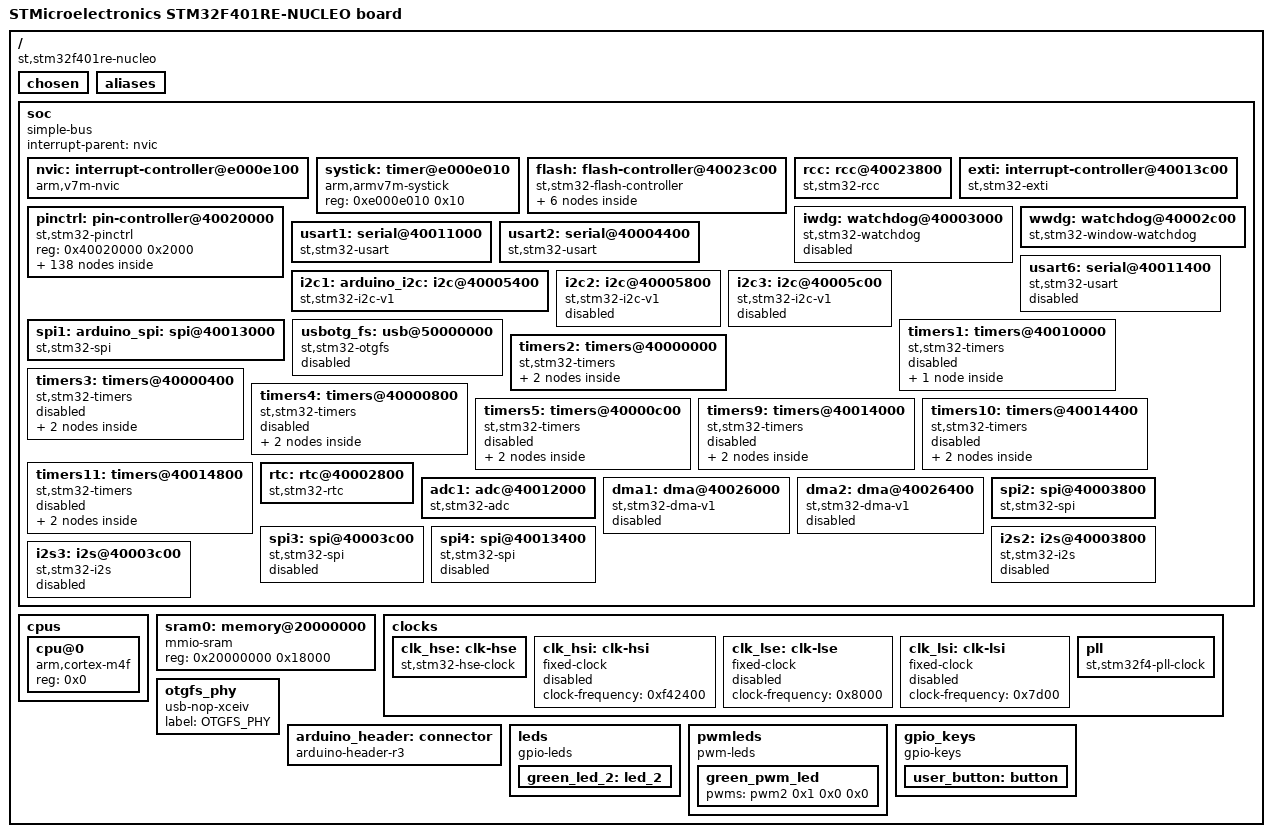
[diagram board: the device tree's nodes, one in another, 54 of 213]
/dts-v1/;

/ {
	#address-cells = < 0x1 >;
	#size-cells = < 0x1 >;
	model = "STMicroelectronics STM32F401RE-NUCLEO board";
	compatible = "st,stm32f401re-nucleo";
	chosen {
		zephyr,flash-controller = &flash;
		zephyr,console = &usart2;
		zephyr,shell-uart = &usart2;
		zephyr,sram = &sram0;
		zephyr,flash = &flash0;
		zephyr,code-partition = &slot0_partition;
	};
	aliases {
		led0 = &green_led_2;
		sw0 = &user_button;
		pwm-led0 = &green_pwm_led;
	};
	soc {
		#address-cells = < 0x1 >;
		#size-cells = < 0x1 >;
		compatible = "simple-bus";
		interrupt-parent = < &nvic >;
		ranges;
		nvic: interrupt-controller@e000e100 {
			#address-cells = < 0x1 >;
			compatible = "arm,v7m-nvic";
			reg = < 0xe000e100 0xc00 >;
			interrupt-controller;
			#interrupt-cells = < 0x2 >;
			arm,num-irq-priority-bits = < 0x4 >;
			phandle = < 0x1 >;
		};
		systick: timer@e000e010 {
			compatible = "arm,armv7m-systick";
			reg = < 0xe000e010 0x10 >;
		};
		flash: flash-controller@40023c00 {
			compatible = "st,stm32-flash-controller", "st,stm32f4-flash-controller";
			label = "FLASH_CTRL";
			reg = < 0x40023c00 0x400 >;
			interrupts = < 0x4 0x0 >;
			#address-cells = < 0x1 >;
			#size-cells = < 0x1 >;
			flash0: flash@8000000 {
				compatible = "st,stm32-nv-flash", "soc-nv-flash";
				label = "FLASH_STM32";
				write-block-size = < 0x1 >;
				max-erase-time = < 0xfa0 >;
				reg = < 0x8000000 0x80000 >;
				partitions {
					compatible = "fixed-partitions";
					#address-cells = < 0x1 >;
					#size-cells = < 0x1 >;
					boot_partition: partition@0 {
						label = "mcuboot";
						reg = < 0x0 0x10000 >;
						read-only;
					};
					slot0_partition: partition@20000 {
						label = "image-0";
						reg = < 0x20000 0x20000 >;
					};
					slot1_partition: partition@40000 {
						label = "image-1";
						reg = < 0x40000 0x20000 >;
					};
					scratch_partition: partition@60000 {
						label = "image-scratch";
						reg = < 0x60000 0x20000 >;
					};
				};
			};
		};
		rcc: rcc@40023800 {
			compatible = "st,stm32-rcc";
			#clock-cells = < 0x2 >;
			reg = < 0x40023800 0x400 >;
			clocks = < &pll >;
			clock-frequency = < 0x501bd00 >;
			ahb-prescaler = < 0x1 >;
			apb1-prescaler = < 0x2 >;
			apb2-prescaler = < 0x1 >;
			phandle = < 0x3 >;
		};
		exti: interrupt-controller@40013c00 {
			compatible = "st,stm32-exti";
			interrupt-controller;
			#interrupt-cells = < 0x1 >;
			reg = < 0x40013c00 0x400 >;
		};
		pinctrl: pin-controller@40020000 {
			compatible = "st,stm32-pinctrl";
			#address-cells = < 0x1 >;
			#size-cells = < 0x1 >;
			reg = < 0x40020000 0x2000 >;
			gpioa: gpio@40020000 {
				compatible = "st,stm32-gpio";
				gpio-controller;
				#gpio-cells = < 0x2 >;
				reg = < 0x40020000 0x400 >;
				clocks = < &rcc 0x0 0x1 >;
				label = "GPIOA";
				phandle = < 0x17 >;
			};
			gpiob: gpio@40020400 {
				compatible = "st,stm32-gpio";
				gpio-controller;
				#gpio-cells = < 0x2 >;
				reg = < 0x40020400 0x400 >;
				clocks = < &rcc 0x0 0x2 >;
				label = "GPIOB";
				phandle = < 0xd >;
			};
			gpioc: gpio@40020800 {
				compatible = "st,stm32-gpio";
				gpio-controller;
				#gpio-cells = < 0x2 >;
				reg = < 0x40020800 0x400 >;
				clocks = < &rcc 0x0 0x4 >;
				label = "GPIOC";
				phandle = < 0x18 >;
			};
			gpiod: gpio@40020c00 {
				compatible = "st,stm32-gpio";
				gpio-controller;
				#gpio-cells = < 0x2 >;
				reg = < 0x40020c00 0x400 >;
				clocks = < &rcc 0x0 0x8 >;
				label = "GPIOD";
			};
			gpioe: gpio@40021000 {
				compatible = "st,stm32-gpio";
				gpio-controller;
				#gpio-cells = < 0x2 >;
				reg = < 0x40021000 0x400 >;
				clocks = < &rcc 0x0 0x10 >;
				label = "GPIOE";
			};
			gpiof: gpio@40021400 {
				compatible = "st,stm32-gpio";
				gpio-controller;
				#gpio-cells = < 0x2 >;
				reg = < 0x40021400 0x400 >;
				clocks = < &rcc 0x0 0x20 >;
				label = "GPIOF";
			};
			gpiog: gpio@40021800 {
				compatible = "st,stm32-gpio";
				gpio-controller;
				#gpio-cells = < 0x2 >;
				reg = < 0x40021800 0x400 >;
				clocks = < &rcc 0x0 0x40 >;
				label = "GPIOG";
			};
			gpioh: gpio@40021c00 {
				compatible = "st,stm32-gpio";
				gpio-controller;
				#gpio-cells = < 0x2 >;
				reg = < 0x40021c00 0x400 >;
				clocks = < &rcc 0x0 0x80 >;
				label = "GPIOH";
			};
			adc1_in0_pa0: adc1_in0_pa0 {
				pinmux = < 0x10 >;
				phandle = < 0x10 >;
			};
			adc1_in1_pa1: adc1_in1_pa1 {
				pinmux = < 0x30 >;
			};
			adc1_in2_pa2: adc1_in2_pa2 {
				pinmux = < 0x50 >;
			};
			adc1_in3_pa3: adc1_in3_pa3 {
				pinmux = < 0x70 >;
			};
			adc1_in4_pa4: adc1_in4_pa4 {
				pinmux = < 0x90 >;
			};
			adc1_in5_pa5: adc1_in5_pa5 {
				pinmux = < 0xb0 >;
			};
			adc1_in6_pa6: adc1_in6_pa6 {
				pinmux = < 0xd0 >;
			};
			adc1_in7_pa7: adc1_in7_pa7 {
				pinmux = < 0xf0 >;
			};
			adc1_in8_pb0: adc1_in8_pb0 {
				pinmux = < 0x210 >;
			};
			adc1_in9_pb1: adc1_in9_pb1 {
				pinmux = < 0x230 >;
			};
			adc1_in10_pc0: adc1_in10_pc0 {
				pinmux = < 0x410 >;
			};
			adc1_in11_pc1: adc1_in11_pc1 {
				pinmux = < 0x430 >;
			};
			adc1_in12_pc2: adc1_in12_pc2 {
				pinmux = < 0x450 >;
			};
			adc1_in13_pc3: adc1_in13_pc3 {
				pinmux = < 0x470 >;
			};
			adc1_in14_pc4: adc1_in14_pc4 {
				pinmux = < 0x490 >;
			};
			adc1_in15_pc5: adc1_in15_pc5 {
				pinmux = < 0x4b0 >;
			};
			i2c1_scl_pb6: i2c1_scl_pb6 {
				pinmux = < 0x2c4 >;
				bias-pull-up;
				drive-open-drain;
			};
			i2c1_scl_pb8: i2c1_scl_pb8 {
				pinmux = < 0x304 >;
				bias-pull-up;
				drive-open-drain;
				phandle = < 0x8 >;
			};
			i2c2_scl_pb10: i2c2_scl_pb10 {
				pinmux = < 0x344 >;
				bias-pull-up;
				drive-open-drain;
			};
			i2c3_scl_pa8: i2c3_scl_pa8 {
				pinmux = < 0x104 >;
				bias-pull-up;
				drive-open-drain;
			};
			i2c1_sda_pb7: i2c1_sda_pb7 {
				pinmux = < 0x2e4 >;
				bias-pull-up;
				drive-open-drain;
			};
			i2c1_sda_pb9: i2c1_sda_pb9 {
				pinmux = < 0x324 >;
				bias-pull-up;
				drive-open-drain;
				phandle = < 0x9 >;
			};
			i2c2_sda_pb3: i2c2_sda_pb3 {
				pinmux = < 0x269 >;
				bias-pull-up;
				drive-open-drain;
			};
			i2c3_sda_pb4: i2c3_sda_pb4 {
				pinmux = < 0x289 >;
				bias-pull-up;
				drive-open-drain;
			};
			i2c3_sda_pc9: i2c3_sda_pc9 {
				pinmux = < 0x524 >;
				bias-pull-up;
				drive-open-drain;
			};
			i2s2_ck_pb10: i2s2_ck_pb10 {
				pinmux = < 0x345 >;
				slew-rate = "very-high-speed";
			};
			i2s2_ck_pb13: i2s2_ck_pb13 {
				pinmux = < 0x3a5 >;
				slew-rate = "very-high-speed";
			};
			i2s3_ck_pb3: i2s3_ck_pb3 {
				pinmux = < 0x266 >;
				slew-rate = "very-high-speed";
			};
			i2s3_ck_pc10: i2s3_ck_pc10 {
				pinmux = < 0x546 >;
				slew-rate = "very-high-speed";
			};
			i2s2_sd_pb15: i2s2_sd_pb15 {
				pinmux = < 0x3e5 >;
			};
			i2s2_sd_pc3: i2s2_sd_pc3 {
				pinmux = < 0x465 >;
			};
			i2s3_sd_pb5: i2s3_sd_pb5 {
				pinmux = < 0x2a6 >;
			};
			i2s3_sd_pc12: i2s3_sd_pc12 {
				pinmux = < 0x586 >;
			};
			i2s2_ws_pb9: i2s2_ws_pb9 {
				pinmux = < 0x325 >;
			};
			i2s2_ws_pb12: i2s2_ws_pb12 {
				pinmux = < 0x385 >;
			};
			i2s3_ws_pa4: i2s3_ws_pa4 {
				pinmux = < 0x86 >;
			};
			i2s3_ws_pa15: i2s3_ws_pa15 {
				pinmux = < 0x1e6 >;
			};
			sdio_d4_pb8: sdio_d4_pb8 {
				pinmux = < 0x30c >;
				bias-pull-up;
				slew-rate = "very-high-speed";
			};
			sdio_d5_pb9: sdio_d5_pb9 {
				pinmux = < 0x32c >;
				bias-pull-up;
				slew-rate = "very-high-speed";
			};
			sdio_d6_pc6: sdio_d6_pc6 {
				pinmux = < 0x4cc >;
				bias-pull-up;
				slew-rate = "very-high-speed";
			};
			sdio_d7_pc7: sdio_d7_pc7 {
				pinmux = < 0x4ec >;
				bias-pull-up;
				slew-rate = "very-high-speed";
			};
			sdio_d0_pc8: sdio_d0_pc8 {
				pinmux = < 0x50c >;
				bias-pull-up;
				slew-rate = "very-high-speed";
			};
			sdio_d1_pc9: sdio_d1_pc9 {
				pinmux = < 0x52c >;
				bias-pull-up;
				slew-rate = "very-high-speed";
			};
			sdio_d2_pc10: sdio_d2_pc10 {
				pinmux = < 0x54c >;
				bias-pull-up;
				slew-rate = "very-high-speed";
			};
			sdio_d3_pc11: sdio_d3_pc11 {
				pinmux = < 0x56c >;
				bias-pull-up;
				slew-rate = "very-high-speed";
			};
			sdio_ck_pc12: sdio_ck_pc12 {
				pinmux = < 0x58c >;
				bias-pull-up;
				slew-rate = "very-high-speed";
			};
			sdio_cmd_pd2: sdio_cmd_pd2 {
				pinmux = < 0x64c >;
				bias-pull-up;
				slew-rate = "very-high-speed";
			};
			spi1_miso_pa6: spi1_miso_pa6 {
				pinmux = < 0xc5 >;
				bias-pull-down;
				phandle = < 0xb >;
			};
			spi1_miso_pb4: spi1_miso_pb4 {
				pinmux = < 0x285 >;
				bias-pull-down;
			};
			spi2_miso_pb14: spi2_miso_pb14 {
				pinmux = < 0x3c5 >;
				bias-pull-down;
				phandle = < 0x13 >;
			};
			spi2_miso_pc2: spi2_miso_pc2 {
				pinmux = < 0x445 >;
				bias-pull-down;
			};
			spi3_miso_pb4: spi3_miso_pb4 {
				pinmux = < 0x286 >;
				bias-pull-down;
			};
			spi3_miso_pc11: spi3_miso_pc11 {
				pinmux = < 0x566 >;
				bias-pull-down;
			};
			spi1_mosi_pa7: spi1_mosi_pa7 {
				pinmux = < 0xe5 >;
				bias-pull-down;
				phandle = < 0xc >;
			};
			spi1_mosi_pb5: spi1_mosi_pb5 {
				pinmux = < 0x2a5 >;
				bias-pull-down;
			};
			spi2_mosi_pb15: spi2_mosi_pb15 {
				pinmux = < 0x3e5 >;
				bias-pull-down;
				phandle = < 0x14 >;
			};
			spi2_mosi_pc3: spi2_mosi_pc3 {
				pinmux = < 0x465 >;
				bias-pull-down;
			};
			spi3_mosi_pb5: spi3_mosi_pb5 {
				pinmux = < 0x2a6 >;
				bias-pull-down;
			};
			spi3_mosi_pc12: spi3_mosi_pc12 {
				pinmux = < 0x586 >;
				bias-pull-down;
			};
			spi1_nss_pa4: spi1_nss_pa4 {
				pinmux = < 0x85 >;
				bias-pull-up;
			};
			spi1_nss_pa15: spi1_nss_pa15 {
				pinmux = < 0x1e5 >;
				bias-pull-up;
			};
			spi2_nss_pb9: spi2_nss_pb9 {
				pinmux = < 0x325 >;
				bias-pull-up;
			};
			spi2_nss_pb12: spi2_nss_pb12 {
				pinmux = < 0x385 >;
				bias-pull-up;
				phandle = < 0x11 >;
			};
			spi3_nss_pa4: spi3_nss_pa4 {
				pinmux = < 0x86 >;
				bias-pull-up;
			};
			spi3_nss_pa15: spi3_nss_pa15 {
				pinmux = < 0x1e6 >;
				bias-pull-up;
			};
			spi1_sck_pa5: spi1_sck_pa5 {
				pinmux = < 0xa5 >;
				bias-pull-down;
				slew-rate = "very-high-speed";
				phandle = < 0xa >;
			};
			spi1_sck_pb3: spi1_sck_pb3 {
				pinmux = < 0x265 >;
				bias-pull-down;
				slew-rate = "very-high-speed";
			};
			spi2_sck_pb10: spi2_sck_pb10 {
				pinmux = < 0x345 >;
				bias-pull-down;
				slew-rate = "very-high-speed";
			};
			spi2_sck_pb13: spi2_sck_pb13 {
				pinmux = < 0x3a5 >;
				bias-pull-down;
				slew-rate = "very-high-speed";
				phandle = < 0x12 >;
			};
			spi3_sck_pb3: spi3_sck_pb3 {
				pinmux = < 0x266 >;
				bias-pull-down;
				slew-rate = "very-high-speed";
			};
			spi3_sck_pc10: spi3_sck_pc10 {
				pinmux = < 0x546 >;
				bias-pull-down;
				slew-rate = "very-high-speed";
			};
			tim10_ch1_pb8: tim10_ch1_pb8 {
				pinmux = < 0x303 >;
			};
			tim1_ch1n_pa7: tim1_ch1n_pa7 {
				pinmux = < 0xe1 >;
			};
			tim1_ch1_pa8: tim1_ch1_pa8 {
				pinmux = < 0x101 >;
			};
			tim1_ch2_pa9: tim1_ch2_pa9 {
				pinmux = < 0x121 >;
			};
			tim1_ch3_pa10: tim1_ch3_pa10 {
				pinmux = < 0x141 >;
			};
			tim1_ch4_pa11: tim1_ch4_pa11 {
				pinmux = < 0x161 >;
			};
			tim1_ch2n_pb0: tim1_ch2n_pb0 {
				pinmux = < 0x201 >;
			};
			tim1_ch3n_pb1: tim1_ch3n_pb1 {
				pinmux = < 0x221 >;
			};
			tim11_ch1_pb9: tim11_ch1_pb9 {
				pinmux = < 0x323 >;
			};
			tim1_ch1n_pb13: tim1_ch1n_pb13 {
				pinmux = < 0x3a1 >;
			};
			tim1_ch2n_pb14: tim1_ch2n_pb14 {
				pinmux = < 0x3c1 >;
			};
			tim1_ch3n_pb15: tim1_ch3n_pb15 {
				pinmux = < 0x3e1 >;
			};
			tim2_ch1_pa0: tim2_ch1_pa0 {
				pinmux = < 0x1 >;
			};
			tim2_ch2_pa1: tim2_ch2_pa1 {
				pinmux = < 0x21 >;
			};
			tim2_ch3_pa2: tim2_ch3_pa2 {
				pinmux = < 0x41 >;
			};
			tim2_ch4_pa3: tim2_ch4_pa3 {
				pinmux = < 0x61 >;
			};
			tim2_ch1_pa5: tim2_ch1_pa5 {
				pinmux = < 0xa1 >;
				phandle = < 0xf >;
			};
			tim2_ch1_pa15: tim2_ch1_pa15 {
				pinmux = < 0x1e1 >;
			};
			tim2_ch2_pb3: tim2_ch2_pb3 {
				pinmux = < 0x261 >;
			};
			tim2_ch3_pb10: tim2_ch3_pb10 {
				pinmux = < 0x341 >;
			};
			tim3_ch1_pa6: tim3_ch1_pa6 {
				pinmux = < 0xc2 >;
			};
			tim3_ch2_pa7: tim3_ch2_pa7 {
				pinmux = < 0xe2 >;
			};
			tim3_ch3_pb0: tim3_ch3_pb0 {
				pinmux = < 0x202 >;
			};
			tim3_ch4_pb1: tim3_ch4_pb1 {
				pinmux = < 0x222 >;
			};
			tim3_ch1_pb4: tim3_ch1_pb4 {
				pinmux = < 0x282 >;
			};
			tim3_ch2_pb5: tim3_ch2_pb5 {
				pinmux = < 0x2a2 >;
			};
			tim3_ch1_pc6: tim3_ch1_pc6 {
				pinmux = < 0x4c2 >;
			};
			tim3_ch2_pc7: tim3_ch2_pc7 {
				pinmux = < 0x4e2 >;
			};
			tim3_ch3_pc8: tim3_ch3_pc8 {
				pinmux = < 0x502 >;
			};
			tim3_ch4_pc9: tim3_ch4_pc9 {
				pinmux = < 0x522 >;
			};
			tim4_ch1_pb6: tim4_ch1_pb6 {
				pinmux = < 0x2c2 >;
			};
			tim4_ch2_pb7: tim4_ch2_pb7 {
				pinmux = < 0x2e2 >;
			};
			tim4_ch3_pb8: tim4_ch3_pb8 {
				pinmux = < 0x302 >;
			};
			tim4_ch4_pb9: tim4_ch4_pb9 {
				pinmux = < 0x322 >;
			};
			tim5_ch1_pa0: tim5_ch1_pa0 {
				pinmux = < 0x2 >;
			};
			tim5_ch2_pa1: tim5_ch2_pa1 {
				pinmux = < 0x22 >;
			};
			tim5_ch3_pa2: tim5_ch3_pa2 {
				pinmux = < 0x42 >;
			};
			tim5_ch4_pa3: tim5_ch4_pa3 {
				pinmux = < 0x62 >;
			};
			tim9_ch1_pa2: tim9_ch1_pa2 {
				pinmux = < 0x43 >;
			};
			tim9_ch2_pa3: tim9_ch2_pa3 {
				pinmux = < 0x63 >;
			};
			usart1_cts_pa11: usart1_cts_pa11 {
				pinmux = < 0x167 >;
				bias-pull-up;
				drive-open-drain;
			};
			usart2_cts_pa0: usart2_cts_pa0 {
				pinmux = < 0x7 >;
				bias-pull-up;
				drive-open-drain;
			};
			usart1_rts_pa12: usart1_rts_pa12 {
				pinmux = < 0x187 >;
				bias-pull-up;
				drive-open-drain;
			};
			usart2_rts_pa1: usart2_rts_pa1 {
				pinmux = < 0x27 >;
				bias-pull-up;
				drive-open-drain;
			};
			usart1_rx_pa10: usart1_rx_pa10 {
				pinmux = < 0x147 >;
			};
			usart1_rx_pb7: usart1_rx_pb7 {
				pinmux = < 0x2e7 >;
				phandle = < 0x5 >;
			};
			usart2_rx_pa3: usart2_rx_pa3 {
				pinmux = < 0x67 >;
				phandle = < 0x7 >;
			};
			usart6_rx_pa12: usart6_rx_pa12 {
				pinmux = < 0x188 >;
			};
			usart6_rx_pc7: usart6_rx_pc7 {
				pinmux = < 0x4e8 >;
			};
			usart1_tx_pa9: usart1_tx_pa9 {
				pinmux = < 0x127 >;
				bias-pull-up;
			};
			usart1_tx_pb6: usart1_tx_pb6 {
				pinmux = < 0x2c7 >;
				bias-pull-up;
				phandle = < 0x4 >;
			};
			usart2_tx_pa2: usart2_tx_pa2 {
				pinmux = < 0x47 >;
				bias-pull-up;
				phandle = < 0x6 >;
			};
			usart6_tx_pa11: usart6_tx_pa11 {
				pinmux = < 0x168 >;
				bias-pull-up;
			};
			usart6_tx_pc6: usart6_tx_pc6 {
				pinmux = < 0x4c8 >;
				bias-pull-up;
			};
			usb_otg_fs_sof_pa8: usb_otg_fs_sof_pa8 {
				pinmux = < 0x10a >;
			};
			usb_otg_fs_vbus_pa9: usb_otg_fs_vbus_pa9 {
				pinmux = < 0x130 >;
			};
			usb_otg_fs_id_pa10: usb_otg_fs_id_pa10 {
				pinmux = < 0x14a >;
			};
			usb_otg_fs_dm_pa11: usb_otg_fs_dm_pa11 {
				pinmux = < 0x16a >;
			};
			usb_otg_fs_dp_pa12: usb_otg_fs_dp_pa12 {
				pinmux = < 0x18a >;
			};
		};
		iwdg: watchdog@40003000 {
			compatible = "st,stm32-watchdog";
			reg = < 0x40003000 0x400 >;
			label = "IWDG";
			status = "disabled";
		};
		wwdg: watchdog@40002c00 {
			compatible = "st,stm32-window-watchdog";
			reg = < 0x40002c00 0x400 >;
			clocks = < &rcc 0x2 0x800 >;
			label = "WWDG";
			interrupts = < 0x0 0x7 >;
			status = "okay";
		};
		usart1: serial@40011000 {
			compatible = "st,stm32-usart", "st,stm32-uart";
			reg = < 0x40011000 0x400 >;
			clocks = < &rcc 0x3 0x10 >;
			interrupts = < 0x25 0x0 >;
			status = "okay";
			label = "UART_1";
			pinctrl-0 = < &usart1_tx_pb6 &usart1_rx_pb7 >;
			pinctrl-names = "default";
			current-speed = < 0x1c200 >;
		};
		usart2: serial@40004400 {
			compatible = "st,stm32-usart", "st,stm32-uart";
			reg = < 0x40004400 0x400 >;
			clocks = < &rcc 0x2 0x20000 >;
			interrupts = < 0x26 0x0 >;
			status = "okay";
			label = "UART_2";
			pinctrl-0 = < &usart2_tx_pa2 &usart2_rx_pa3 >;
			pinctrl-names = "default";
			current-speed = < 0x1c200 >;
		};
		usart6: serial@40011400 {
			compatible = "st,stm32-usart", "st,stm32-uart";
			reg = < 0x40011400 0x400 >;
			clocks = < &rcc 0x3 0x20 >;
			interrupts = < 0x47 0x0 >;
			status = "disabled";
			label = "UART_6";
		};
		i2c1: arduino_i2c: i2c@40005400 {
			compatible = "st,stm32-i2c-v1";
			clock-frequency = < 0x61a80 >;
			#address-cells = < 0x1 >;
			#size-cells = < 0x0 >;
			reg = < 0x40005400 0x400 >;
			clocks = < &rcc 0x2 0x200000 >;
			interrupts = < 0x1f 0x0 >, < 0x20 0x0 >;
			interrupt-names = "event", "error";
			status = "okay";
			label = "I2C_1";
			pinctrl-0 = < &i2c1_scl_pb8 &i2c1_sda_pb9 >;
			pinctrl-names = "default";
		};
		i2c2: i2c@40005800 {
			compatible = "st,stm32-i2c-v1";
			clock-frequency = < 0x186a0 >;
			#address-cells = < 0x1 >;
			#size-cells = < 0x0 >;
			reg = < 0x40005800 0x400 >;
			clocks = < &rcc 0x2 0x400000 >;
			interrupts = < 0x21 0x0 >, < 0x22 0x0 >;
			interrupt-names = "event", "error";
			status = "disabled";
			label = "I2C_2";
		};
		i2c3: i2c@40005c00 {
			compatible = "st,stm32-i2c-v1";
			clock-frequency = < 0x186a0 >;
			#address-cells = < 0x1 >;
			#size-cells = < 0x0 >;
			reg = < 0x40005c00 0x400 >;
			clocks = < &rcc 0x2 0x800000 >;
			interrupts = < 0x48 0x0 >, < 0x49 0x0 >;
			interrupt-names = "event", "error";
			status = "disabled";
			label = "I2C_3";
		};
		spi1: arduino_spi: spi@40013000 {
			compatible = "st,stm32-spi";
			#address-cells = < 0x1 >;
			#size-cells = < 0x0 >;
			reg = < 0x40013000 0x400 >;
			clocks = < &rcc 0x3 0x1000 >;
			interrupts = < 0x23 0x5 >;
			status = "okay";
			label = "SPI_1";
			pinctrl-0 = < &spi1_sck_pa5 &spi1_miso_pa6 &spi1_mosi_pa7 >;
			pinctrl-names = "default";
			cs-gpios = < &gpiob 0x6 0x11 >;
		};
		usbotg_fs: usb@50000000 {
			compatible = "st,stm32-otgfs";
			reg = < 0x50000000 0x40000 >;
			interrupts = < 0x43 0x0 >;
			interrupt-names = "otgfs";
			num-bidir-endpoints = < 0x4 >;
			ram-size = < 0x500 >;
			maximum-speed = "full-speed";
			phys = < &otgfs_phy >;
			clocks = < &rcc 0x1 0x80 >;
			status = "disabled";
			label = "OTGFS";
		};
		timers1: timers@40010000 {
			compatible = "st,stm32-timers";
			reg = < 0x40010000 0x400 >;
			clocks = < &rcc 0x3 0x1 >;
			interrupts = < 0x18 0x0 >, < 0x19 0x0 >, < 0x1a 0x0 >, < 0x1b 0x0 >;
			interrupt-names = "brk", "up", "trgcom", "cc";
			st,prescaler = < 0x0 >;
			status = "disabled";
			label = "TIMERS_1";
			pwm {
				compatible = "st,stm32-pwm";
				status = "disabled";
				label = "PWM_1";
				#pwm-cells = < 0x3 >;
			};
		};
		timers2: timers@40000000 {
			compatible = "st,stm32-timers";
			reg = < 0x40000000 0x400 >;
			clocks = < &rcc 0x2 0x1 >;
			interrupts = < 0x1c 0x0 >;
			interrupt-names = "global";
			st,prescaler = < 0x0 >;
			status = "okay";
			label = "TIMERS_2";
			pwm2: pwm {
				compatible = "st,stm32-pwm";
				status = "okay";
				label = "PWM_2";
				#pwm-cells = < 0x3 >;
				pinctrl-0 = < &tim2_ch1_pa5 >;
				pinctrl-names = "default";
				phandle = < 0x19 >;
			};
			counter {
				compatible = "st,stm32-counter";
				status = "disabled";
				label = "COUNTER_2";
			};
		};
		timers3: timers@40000400 {
			compatible = "st,stm32-timers";
			reg = < 0x40000400 0x400 >;
			clocks = < &rcc 0x2 0x2 >;
			interrupts = < 0x1d 0x0 >;
			interrupt-names = "global";
			st,prescaler = < 0x0 >;
			status = "disabled";
			label = "TIMERS_3";
			pwm {
				compatible = "st,stm32-pwm";
				status = "disabled";
				label = "PWM_3";
				#pwm-cells = < 0x3 >;
			};
			counter {
				compatible = "st,stm32-counter";
				status = "disabled";
				label = "COUNTER_3";
			};
		};
		timers4: timers@40000800 {
			compatible = "st,stm32-timers";
			reg = < 0x40000800 0x400 >;
			clocks = < &rcc 0x2 0x4 >;
			interrupts = < 0x1e 0x0 >;
			interrupt-names = "global";
			st,prescaler = < 0x0 >;
			status = "disabled";
			label = "TIMERS_4";
			pwm {
				compatible = "st,stm32-pwm";
				status = "disabled";
				label = "PWM_4";
				#pwm-cells = < 0x3 >;
			};
			counter {
				compatible = "st,stm32-counter";
				status = "disabled";
				label = "COUNTER_4";
			};
		};
		timers5: timers@40000c00 {
			compatible = "st,stm32-timers";
			reg = < 0x40000c00 0x400 >;
			clocks = < &rcc 0x2 0x8 >;
			interrupts = < 0x32 0x0 >;
			interrupt-names = "global";
			st,prescaler = < 0x0 >;
			status = "disabled";
			label = "TIMERS_5";
			pwm {
				compatible = "st,stm32-pwm";
				status = "disabled";
				label = "PWM_5";
				#pwm-cells = < 0x3 >;
			};
			counter {
				compatible = "st,stm32-counter";
				status = "disabled";
				label = "COUNTER_5";
			};
		};
		timers9: timers@40014000 {
			compatible = "st,stm32-timers";
			reg = < 0x40014000 0x400 >;
			clocks = < &rcc 0x3 0x10000 >;
			interrupts = < 0x18 0x0 >;
			interrupt-names = "global";
			st,prescaler = < 0x0 >;
			status = "disabled";
			label = "TIMERS_9";
			pwm {
				compatible = "st,stm32-pwm";
				status = "disabled";
				label = "PWM_9";
				#pwm-cells = < 0x3 >;
			};
			counter {
				compatible = "st,stm32-counter";
				status = "disabled";
				label = "COUNTER_9";
			};
		};
		timers10: timers@40014400 {
			compatible = "st,stm32-timers";
			reg = < 0x40014400 0x400 >;
			clocks = < &rcc 0x3 0x20000 >;
			interrupts = < 0x19 0x0 >;
			interrupt-names = "global";
			st,prescaler = < 0x0 >;
			status = "disabled";
			label = "TIMERS_10";
			pwm {
				compatible = "st,stm32-pwm";
				status = "disabled";
				label = "PWM_10";
				#pwm-cells = < 0x3 >;
			};
			counter {
				compatible = "st,stm32-counter";
				status = "disabled";
				label = "COUNTER_10";
			};
		};
		timers11: timers@40014800 {
			compatible = "st,stm32-timers";
			reg = < 0x40014800 0x400 >;
			clocks = < &rcc 0x3 0x40000 >;
			interrupts = < 0x1a 0x0 >;
			interrupt-names = "global";
			st,prescaler = < 0x0 >;
			status = "disabled";
			label = "TIMERS_11";
			pwm {
				compatible = "st,stm32-pwm";
				status = "disabled";
				label = "PWM_11";
				#pwm-cells = < 0x3 >;
			};
			counter {
				compatible = "st,stm32-counter";
				status = "disabled";
				label = "COUNTER_11";
			};
		};
		rtc: rtc@40002800 {
			compatible = "st,stm32-rtc";
			reg = < 0x40002800 0x400 >;
			interrupts = < 0x29 0x0 >;
			clocks = < &rcc 0x2 0x10000000 >;
			prescaler = < 0x8000 >;
			status = "okay";
			label = "RTC_0";
		};
		adc1: adc@40012000 {
			compatible = "st,stm32-adc";
			reg = < 0x40012000 0x400 >;
			clocks = < &rcc 0x3 0x100 >;
			interrupts = < 0x12 0x0 >;
			status = "okay";
			label = "ADC_1";
			#io-channel-cells = < 0x1 >;
			pinctrl-0 = < &adc1_in0_pa0 >;
			pinctrl-names = "default";
		};
		dma1: dma@40026000 {
			compatible = "st,stm32-dma-v1";
			#dma-cells = < 0x4 >;
			reg = < 0x40026000 0x400 >;
			interrupts = < 0xb 0x0 0xc 0x0 0xd 0x0 0xe 0x0 0xf 0x0 0x10 0x0 0x11 0x0 0x2f 0x0 >;
			clocks = < &rcc 0x0 0x200000 >;
			status = "disabled";
			label = "DMA_1";
			phandle = < 0x15 >;
		};
		dma2: dma@40026400 {
			compatible = "st,stm32-dma-v1";
			#dma-cells = < 0x4 >;
			reg = < 0x40026400 0x400 >;
			interrupts = < 0x38 0x0 0x39 0x0 0x3a 0x0 0x3b 0x0 0x3c 0x0 0x44 0x0 0x45 0x0 0x46 0x0 >;
			clocks = < &rcc 0x0 0x400000 >;
			st,mem2mem;
			status = "disabled";
			label = "DMA_2";
		};
		spi2: spi@40003800 {
			compatible = "st,stm32-spi";
			#address-cells = < 0x1 >;
			#size-cells = < 0x0 >;
			reg = < 0x40003800 0x400 >;
			clocks = < &rcc 0x2 0x4000 >;
			interrupts = < 0x24 0x5 >;
			status = "okay";
			label = "SPI_2";
			pinctrl-0 = < &spi2_nss_pb12 &spi2_sck_pb13 &spi2_miso_pb14 &spi2_mosi_pb15 >;
			pinctrl-names = "default";
		};
		spi3: spi@40003c00 {
			compatible = "st,stm32-spi";
			#address-cells = < 0x1 >;
			#size-cells = < 0x0 >;
			reg = < 0x40003c00 0x400 >;
			clocks = < &rcc 0x2 0x8000 >;
			interrupts = < 0x33 0x5 >;
			status = "disabled";
			label = "SPI_3";
		};
		spi4: spi@40013400 {
			compatible = "st,stm32-spi";
			#address-cells = < 0x1 >;
			#size-cells = < 0x0 >;
			reg = < 0x40013400 0x400 >;
			clocks = < &rcc 0x3 0x2000 >;
			interrupts = < 0x54 0x5 >;
			status = "disabled";
			label = "SPI_4";
		};
		i2s2: i2s@40003800 {
			compatible = "st,stm32-i2s";
			#address-cells = < 0x1 >;
			#size-cells = < 0x0 >;
			reg = < 0x40003800 0x400 >;
			clocks = < &rcc 0x2 0x4000 >;
			interrupts = < 0x24 0x5 >;
			dmas = < &dma1 0x4 0x0 0x400 0x3 &dma1 0x3 0x0 0x400 0x3 >;
			dma-names = "tx", "rx";
			status = "disabled";
			label = "I2S_2";
		};
		i2s3: i2s@40003c00 {
			compatible = "st,stm32-i2s";
			#address-cells = < 0x1 >;
			#size-cells = < 0x0 >;
			reg = < 0x40003c00 0x400 >;
			clocks = < &rcc 0x2 0x8000 >;
			interrupts = < 0x33 0x5 >;
			dmas = < &dma1 0x5 0x0 0x400 0x3 &dma1 0x0 0x0 0x400 0x3 >;
			dma-names = "tx", "rx";
			status = "disabled";
			label = "I2S_3";
		};
	};
	cpus {
		#address-cells = < 0x1 >;
		#size-cells = < 0x0 >;
		cpu@0 {
			device_type = "cpu";
			compatible = "arm,cortex-m4f";
			reg = < 0x0 >;
		};
	};
	sram0: memory@20000000 {
		compatible = "mmio-sram";
		reg = < 0x20000000 0x18000 >;
	};
	clocks {
		clk_hse: clk-hse {
			#clock-cells = < 0x0 >;
			compatible = "st,stm32-hse-clock";
			status = "okay";
			hse-bypass;
			clock-frequency = < 0x7a1200 >;
			phandle = < 0x16 >;
		};
		clk_hsi: clk-hsi {
			#clock-cells = < 0x0 >;
			compatible = "fixed-clock";
			clock-frequency = < 0xf42400 >;
			status = "disabled";
		};
		clk_lse: clk-lse {
			#clock-cells = < 0x0 >;
			compatible = "fixed-clock";
			clock-frequency = < 0x8000 >;
			status = "disabled";
		};
		clk_lsi: clk-lsi {
			#clock-cells = < 0x0 >;
			compatible = "fixed-clock";
			clock-frequency = < 0x7d00 >;
			status = "disabled";
		};
		pll: pll {
			#clock-cells = < 0x0 >;
			compatible = "st,stm32f4-pll-clock";
			status = "okay";
			div-m = < 0x8 >;
			mul-n = < 0x150 >;
			div-p = < 0x4 >;
			div-q = < 0x7 >;
			clocks = < &clk_hse >;
			phandle = < 0x2 >;
		};
	};
	otgfs_phy: otgfs_phy {
		compatible = "usb-nop-xceiv";
		#phy-cells = < 0x0 >;
		label = "OTGFS_PHY";
		phandle = < 0xe >;
	};
	arduino_header: connector {
		compatible = "arduino-header-r3";
		#gpio-cells = < 0x2 >;
		gpio-map-mask = < 0xffffffff 0xffffffc0 >;
		gpio-map-pass-thru = < 0x0 0x3f >;
		gpio-map = < 0x0 0x0 &gpioa 0x0 0x0 >, < 0x1 0x0 &gpioa 0x1 0x0 >, < 0x2 0x0 &gpioa 0x4 0x0 >, < 0x3 0x0 &gpiob 0x0 0x0 >, < 0x4 0x0 &gpioc 0x1 0x0 >, < 0x5 0x0 &gpioc 0x0 0x0 >, < 0x6 0x0 &gpioa 0x3 0x0 >, < 0x7 0x0 &gpioa 0x2 0x0 >, < 0x8 0x0 &gpioa 0xa 0x0 >, < 0x9 0x0 &gpiob 0x3 0x0 >, < 0xa 0x0 &gpiob 0x5 0x0 >, < 0xb 0x0 &gpiob 0x4 0x0 >, < 0xc 0x0 &gpiob 0xa 0x0 >, < 0xd 0x0 &gpioa 0x8 0x0 >, < 0xe 0x0 &gpioa 0x9 0x0 >, < 0xf 0x0 &gpioc 0x7 0x0 >, < 0x10 0x0 &gpiob 0x6 0x0 >, < 0x11 0x0 &gpioa 0x7 0x0 >, < 0x12 0x0 &gpioa 0x6 0x0 >, < 0x13 0x0 &gpioa 0x5 0x0 >, < 0x14 0x0 &gpiob 0x9 0x0 >, < 0x15 0x0 &gpiob 0x8 0x0 >;
	};
	leds {
		compatible = "gpio-leds";
		green_led_2: led_2 {
			gpios = < &gpioa 0x5 0x0 >;
			label = "User LD2";
		};
	};
	pwmleds {
		compatible = "pwm-leds";
		green_pwm_led: green_pwm_led {
			pwms = < &pwm2 0x1 0x0 0x0 >;
		};
	};
	gpio_keys {
		compatible = "gpio-keys";
		user_button: button {
			label = "User";
			gpios = < &gpioc 0xd 0x1 >;
		};
	};
};
